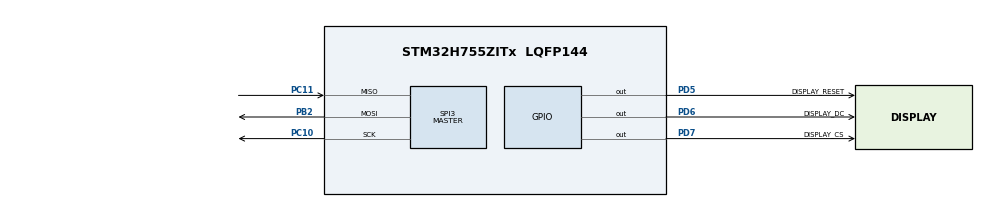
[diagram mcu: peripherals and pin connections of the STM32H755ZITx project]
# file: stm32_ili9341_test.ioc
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CortexM4.IPs=FATFS_M4\:I,FREERTOS_M4\:I,IWDG2\:I,RCC,WWDG2\:I,DMA,BDMA,MDMA,NVIC2\:I,DEBUG,PDM2PCM_M4\:I,PWR,RESMGR_UTILITY,SYS_M4\:I,USB_DEVICE_M4\:I,USB_HOST_M4\:I,CORTEX_M4\:I,GPIO,OPENAMP_M4\:I,VREFBUF,LPTIM3\:I
CortexM7.IPs=FATFS_M7\:I,FREERTOS_M7\:I,IWDG1\:I,RCC\:I,WWDG1\:I,DMA\:I,BDMA\:I,MDMA\:I,NVIC1\:I,SYS\:I,CORTEX_M7\:I,DEBUG\:I,PDM2PCM_M7\:I,PWR\:I,RESMGR_UTILITY\:I,USB_DEVICE_M7\:I,USB_HOST_M7\:I,GPIO\:I,OPENAMP_M7\:I,VREFBUF\:I,SPI3\:I,STMicroelectronics.X-CUBE-TOUCHGFX.4.22.1_M7\:I,CRC\:I
CortexM7.Pins=PD5,PD6,PD7
Mcu.Family=STM32H7
Mcu.Name=STM32H755ZITx
Mcu.Package=LQFP144
NVIC1.PriorityGroup=NVIC_PRIORITYGROUP_4
NVIC2.PriorityGroup=NVIC_PRIORITYGROUP_4
PA13\ (JTMS/SWDIO).PinAttribute=CortexM7
PA13\ (JTMS/SWDIO).Signal=DEBUG_JTMS-SWDIO
PA14\ (JTCK/SWCLK).PinAttribute=CortexM7
PA14\ (JTCK/SWCLK).Signal=DEBUG_JTCK-SWCLK
PB2.Mode=Full_Duplex_Master
PB2.PinAttribute=CortexM7
PB2.Signal=SPI3_MOSI
PC10.Mode=Full_Duplex_Master
PC10.PinAttribute=CortexM7
PC10.Signal=SPI3_SCK
PC11.Mode=Full_Duplex_Master
PC11.PinAttribute=CortexM7
PC11.Signal=SPI3_MISO
PD14.Signal=FMC_D0_DA0
PD5.GPIO_Label=DISPLAY_RESET
PD5.PinAttribute=CortexM7
PD5.PinState=GPIO_PIN_SET
PD5.Signal=GPIO_Output
PD6.GPIO_Label=DISPLAY_DC
PD6.PinAttribute=CortexM7
PD6.Signal=GPIO_Output
PD7.GPIO_Label=DISPLAY_CS
PD7.PinAttribute=CortexM7
PD7.PinState=GPIO_PIN_SET
PD7.Signal=GPIO_Output
PH0-OSC_IN\ (PH0).Mode=HSE-External-Oscillator
PH0-OSC_IN\ (PH0).PinAttribute=CortexM7
PH0-OSC_IN\ (PH0).Signal=RCC_OSC_IN
PH1-OSC_OUT\ (PH1).Mode=HSE-External-Oscillator
PH1-OSC_OUT\ (PH1).PinAttribute=CortexM7
PH1-OSC_OUT\ (PH1).Signal=RCC_OSC_OUT
ProjectManager.HeapSize=M4-0x200,M7-0x200
ProjectManager.StackSize=M4-0x400,M7-0x400
ProjectManager.TargetToolchain=STM32CubeIDE
RCC.ADCFreq_Value=34133333.33333333
RCC.APB1Freq_Value=75000000
RCC.APB2Freq_Value=75000000
RCC.APB3Freq_Value=75000000
RCC.APB4Freq_Value=75000000
RCC.CortexFreq_Value=75000000
RCC.DIVM1=4
RCC.DIVM2=27
RCC.DIVN1=9
RCC.DIVN2=72
RCC.DIVP2=5
RCC.DIVQ1=120
RCC.HCLKFreq_Value=75000000
RCC.PLL2FRACN=0
RCC.PLL3FRACN=0
RCC.PLLFRACN=3072
RCC.SPI123CLockSelection=RCC_SPI123CLKSOURCE_PLL2
RCC.SYSCLKFreq_VALUE=75000000
RCC.SYSCLKSource=RCC_SYSCLKSOURCE_PLLCLK
RCC.SupplySource=PWR_DIRECT_SMPS_SUPPLY
RCC.USBFreq_Value=1250000
SH.FMC_D0_DA0.0=FMC_D0
SPI3.CRCCalculation=SPI_CRCCALCULATION_DISABLE
SPI3.CalculateBaudRate=17.066666 MBits/s
SPI3.DataSize=SPI_DATASIZE_8BIT
SPI3.Direction=SPI_DIRECTION_2LINES
SPI3.Mode=SPI_MODE_MASTER
SPI3.VirtualType=VM_MASTER
STMicroelectronics.X-CUBE-TOUCHGFX.4.22.1_IsPackSelfContextualization=true
STMicroelectronics.X-CUBE-TOUCHGFX.4.22.1_M7.tgfx_buffering_strategy=Partial
STMicroelectronics.X-CUBE-TOUCHGFX.4.22.1_M7.tgfx_custom_height=240
STMicroelectronics.X-CUBE-TOUCHGFX.4.22.1_M7.tgfx_custom_width=320
STMicroelectronics.X-CUBE-TOUCHGFX.4.22.1_M7.tgfx_oswrapper=NoOS
VP_CRC_VS_CRC.Mode=CRC_Activate
VP_SYS_M4_VS_Systick.Mode=SysTick
board=NUCLEO-H755ZI-Q

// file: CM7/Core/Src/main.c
/* USER CODE BEGIN Header */
/**
  ******************************************************************************
  * @file           : main.c
  * @brief          : Main program body
  ******************************************************************************
  * @attention
  *
  * Copyright (c) 2023 STMicroelectronics.
  * All rights reserved.
  *
  * This software is licensed under terms that can be found in the LICENSE file
  * in the root directory of this software component.
  * If no LICENSE file comes with this software, it is provided AS-IS.
  *
  ******************************************************************************
  */
/* USER CODE END Header */
#include "main.h"

/* USER CODE BEGIN Includes */

//#include "ili9341.h"

//#include "ILI9341_Touchscreen.h"

#include "ILI9341_STM32_Driver.h"
#include "ILI9341_GFX.h"
#include <stdio.h>
#include "snow_tiger.h"
#include "stm32h7xx_hal.h"
/* USER CODE END Includes */

/* USER CODE BEGIN PD */

#ifndef HSEM_ID_0
#define HSEM_ID_0 (0U) /* HW semaphore 0*/
#endif
/* USER CODE END PD */

CRC_HandleTypeDef hcrc;

SPI_HandleTypeDef hspi3;

void SystemClock_Config(void);
static void MX_GPIO_Init(void);
static void MX_SPI3_Init(void);
static void MX_CRC_Init(void);

/* USER CODE BEGIN 0 */
// Function to initialize SPI1

/* USER CODE END 0 */

int main(void)
{
/* USER CODE BEGIN Boot_Mode_Sequence_0 */
  int32_t timeout;
/* USER CODE END Boot_Mode_Sequence_0 */

/* USER CODE BEGIN Boot_Mode_Sequence_1 */
  /* Wait until CPU2 boots and enters in stop mode or timeout*/
  timeout = 0xFFFF;
  while((__HAL_RCC_GET_FLAG(RCC_FLAG_D2CKRDY) != RESET) && (timeout-- > 0));
  if ( timeout < 0 )
  {
  Error_Handler();
  }
/* USER CODE END Boot_Mode_Sequence_1 */
  /* MCU Configuration--------------------------------------------------------*/

  /* Reset of all peripherals, Initializes the Flash interface and the Systick. */
  HAL_Init();

  /* USER CODE BEGIN Init */
//  GraphicsInit();
//  TouchCalibrate();
//  GraphicsClear(BLUE);
  /* USER CODE END Init */

  /* Configure the system clock */
  SystemClock_Config();
/* USER CODE BEGIN Boot_Mode_Sequence_2 */
/* When system initialization is finished, Cortex-M7 will release Cortex-M4 by means of
HSEM notification */
/*HW semaphore Clock enable*/
__HAL_RCC_HSEM_CLK_ENABLE();
/*Take HSEM */
HAL_HSEM_FastTake(HSEM_ID_0);
/*Release HSEM in order to notify the CPU2(CM4)*/
HAL_HSEM_Release(HSEM_ID_0,0);
/* wait until CPU2 wakes up from stop mode */
timeout = 0xFFFF;
while((__HAL_RCC_GET_FLAG(RCC_FLAG_D2CKRDY) == RESET) && (timeout-- > 0));
if ( timeout < 0 )
{
Error_Handler();
}
/* USER CODE END Boot_Mode_Sequence_2 */

  /* Initialize all configured peripherals */
  MX_GPIO_Init();
  MX_SPI3_Init();
  MX_CRC_Init();

  /* Infinite loop */
  /* USER CODE BEGIN WHILE */

  ILI9341_Init();

//  MX_TouchGFX_Init();
//
//  uint32_t my_display = 0;
//  BSP_LCD_Init(my_display, LCD_ORIENTATION_PORTRAIT);
//
//  uint8_t color = 0;
//  uint8_t rect[10] ={ color,color,color,color,color,color,color,color,color,color};
//  uint8_t status_u8=0;
//  status_u8 = BSP_LCD_FillRGBRect(my_display, 0, rect, 100, 100, 10, 1);
  while (1)
  {
//	  ILI9341_Fill_Screen(WHITE);
//	  		ILI9341_Set_Rotation(SCREEN_HORIZONTAL_2);
//	  		ILI9341_Draw_Text("FPS TEST, 40 loop 2 screens", 10, 10, BLACK, 1, WHITE);
//	  		HAL_Delay(2000);
//	  		ILI9341_Fill_Screen(WHITE);
//
//
//	  //----------------------------------------------------------IMAGE EXAMPLE, Snow Tiger
//	  		ILI9341_Fill_Screen(WHITE);
//	  		ILI9341_Set_Rotation(SCREEN_HORIZONTAL_2);
//	  		ILI9341_Draw_Text("RGB Picture", 10, 10, BLACK, 1, WHITE);
//	  		ILI9341_Draw_Text("TIGER", 10, 20, BLACK, 1, WHITE);
//	  		HAL_Delay(2000);
//	  		ILI9341_Draw_Image((const char*)snow_tiger, SCREEN_VERTICAL_2);
//	  		ILI9341_Set_Rotation(SCREEN_VERTICAL_1);
//	  		HAL_Delay(10000);
//	  MX_TouchGFX_Process();

	  HAL_Delay(2000);

    /* USER CODE END WHILE */

  }
}

void SystemClock_Config(void)
{
  RCC_OscInitTypeDef RCC_OscInitStruct = {0};
  RCC_ClkInitTypeDef RCC_ClkInitStruct = {0};

  /** Supply configuration update enable
  */
  HAL_PWREx_ConfigSupply(PWR_DIRECT_SMPS_SUPPLY);

  /** Configure the main internal regulator output voltage
  */
  __HAL_PWR_VOLTAGESCALING_CONFIG(PWR_REGULATOR_VOLTAGE_SCALE3);

  while(!__HAL_PWR_GET_FLAG(PWR_FLAG_VOSRDY)) {}

  /** Macro to configure the PLL clock source
  */
  __HAL_RCC_PLL_PLLSOURCE_CONFIG(RCC_PLLSOURCE_HSI);

  /** Initializes the RCC Oscillators according to the specified parameters
  * in the RCC_OscInitTypeDef structure.
  */
  RCC_OscInitStruct.OscillatorType = RCC_OSCILLATORTYPE_HSI;
  RCC_OscInitStruct.HSIState = RCC_HSI_DIV1;
  RCC_OscInitStruct.HSICalibrationValue = RCC_HSICALIBRATION_DEFAULT;
  RCC_OscInitStruct.PLL.PLLState = RCC_PLL_ON;
  RCC_OscInitStruct.PLL.PLLSource = RCC_PLLSOURCE_HSI;
  RCC_OscInitStruct.PLL.PLLM = 4;
  RCC_OscInitStruct.PLL.PLLN = 9;
  RCC_OscInitStruct.PLL.PLLP = 2;
  RCC_OscInitStruct.PLL.PLLQ = 120;
  RCC_OscInitStruct.PLL.PLLR = 2;
  RCC_OscInitStruct.PLL.PLLRGE = RCC_PLL1VCIRANGE_3;
  RCC_OscInitStruct.PLL.PLLVCOSEL = RCC_PLL1VCOMEDIUM;
  RCC_OscInitStruct.PLL.PLLFRACN = 3072;
  if (HAL_RCC_OscConfig(&RCC_OscInitStruct) != HAL_OK)
  {
    Error_Handler();
  }

  /** Initializes the CPU, AHB and APB buses clocks
  */
  RCC_ClkInitStruct.ClockType = RCC_CLOCKTYPE_HCLK|RCC_CLOCKTYPE_SYSCLK
                              |RCC_CLOCKTYPE_PCLK1|RCC_CLOCKTYPE_PCLK2
                              |RCC_CLOCKTYPE_D3PCLK1|RCC_CLOCKTYPE_D1PCLK1;
  RCC_ClkInitStruct.SYSCLKSource = RCC_SYSCLKSOURCE_PLLCLK;
  RCC_ClkInitStruct.SYSCLKDivider = RCC_SYSCLK_DIV1;
  RCC_ClkInitStruct.AHBCLKDivider = RCC_HCLK_DIV1;
  RCC_ClkInitStruct.APB3CLKDivider = RCC_APB3_DIV1;
  RCC_ClkInitStruct.APB1CLKDivider = RCC_APB1_DIV1;
  RCC_ClkInitStruct.APB2CLKDivider = RCC_APB2_DIV1;
  RCC_ClkInitStruct.APB4CLKDivider = RCC_APB4_DIV1;

  if (HAL_RCC_ClockConfig(&RCC_ClkInitStruct, FLASH_LATENCY_1) != HAL_OK)
  {
    Error_Handler();
  }
}

static void MX_CRC_Init(void)
{

  hcrc.Instance = CRC;
  hcrc.Init.DefaultPolynomialUse = DEFAULT_POLYNOMIAL_ENABLE;
  hcrc.Init.DefaultInitValueUse = DEFAULT_INIT_VALUE_ENABLE;
  hcrc.Init.InputDataInversionMode = CRC_INPUTDATA_INVERSION_NONE;
  hcrc.Init.OutputDataInversionMode = CRC_OUTPUTDATA_INVERSION_DISABLE;
  hcrc.InputDataFormat = CRC_INPUTDATA_FORMAT_BYTES;
  if (HAL_CRC_Init(&hcrc) != HAL_OK)
  {
    Error_Handler();
  }

}

static void MX_SPI3_Init(void)
{

  /* SPI3 parameter configuration*/
  hspi3.Instance = SPI3;
  hspi3.Init.Mode = SPI_MODE_MASTER;
  hspi3.Init.Direction = SPI_DIRECTION_2LINES;
  hspi3.Init.DataSize = SPI_DATASIZE_8BIT;
  hspi3.Init.CLKPolarity = SPI_POLARITY_LOW;
  hspi3.Init.CLKPhase = SPI_PHASE_1EDGE;
  hspi3.Init.NSS = SPI_NSS_SOFT;
  hspi3.Init.BaudRatePrescaler = SPI_BAUDRATEPRESCALER_2;
  hspi3.Init.FirstBit = SPI_FIRSTBIT_MSB;
  hspi3.Init.TIMode = SPI_TIMODE_DISABLE;
  hspi3.Init.CRCCalculation = SPI_CRCCALCULATION_DISABLE;
  hspi3.Init.CRCPolynomial = 0x0;
  hspi3.Init.NSSPMode = SPI_NSS_PULSE_ENABLE;
  hspi3.Init.NSSPolarity = SPI_NSS_POLARITY_LOW;
  hspi3.Init.FifoThreshold = SPI_FIFO_THRESHOLD_01DATA;
  hspi3.Init.TxCRCInitializationPattern = SPI_CRC_INITIALIZATION_ALL_ZERO_PATTERN;
  hspi3.Init.RxCRCInitializationPattern = SPI_CRC_INITIALIZATION_ALL_ZERO_PATTERN;
  hspi3.Init.MasterSSIdleness = SPI_MASTER_SS_IDLENESS_00CYCLE;
  hspi3.Init.MasterInterDataIdleness = SPI_MASTER_INTERDATA_IDLENESS_00CYCLE;
  hspi3.Init.MasterReceiverAutoSusp = SPI_MASTER_RX_AUTOSUSP_DISABLE;
  hspi3.Init.MasterKeepIOState = SPI_MASTER_KEEP_IO_STATE_DISABLE;
  hspi3.Init.IOSwap = SPI_IO_SWAP_DISABLE;
  if (HAL_SPI_Init(&hspi3) != HAL_OK)
  {
    Error_Handler();
  }

}

static void MX_GPIO_Init(void)
{
  GPIO_InitTypeDef GPIO_InitStruct = {0};

  /* GPIO Ports Clock Enable */
  __HAL_RCC_GPIOH_CLK_ENABLE();
  __HAL_RCC_GPIOB_CLK_ENABLE();
  __HAL_RCC_GPIOA_CLK_ENABLE();
  __HAL_RCC_GPIOC_CLK_ENABLE();
  __HAL_RCC_GPIOD_CLK_ENABLE();

  /*Configure GPIO pin Output Level */
  HAL_GPIO_WritePin(GPIOD, DISPLAY_RESET_Pin|DISPLAY_CS_Pin, GPIO_PIN_SET);

  /*Configure GPIO pin Output Level */
  HAL_GPIO_WritePin(DISPLAY_DC_GPIO_Port, DISPLAY_DC_Pin, GPIO_PIN_RESET);

  /*Configure GPIO pins : DISPLAY_RESET_Pin DISPLAY_DC_Pin DISPLAY_CS_Pin */
  GPIO_InitStruct.Pin = DISPLAY_RESET_Pin|DISPLAY_DC_Pin|DISPLAY_CS_Pin;
  GPIO_InitStruct.Mode = GPIO_MODE_OUTPUT_PP;
  GPIO_InitStruct.Pull = GPIO_NOPULL;
  GPIO_InitStruct.Speed = GPIO_SPEED_FREQ_LOW;
  HAL_GPIO_Init(GPIOD, &GPIO_InitStruct);

}

void Error_Handler(void)
{
  __disable_irq();
  while (1)
  {
  }
}
